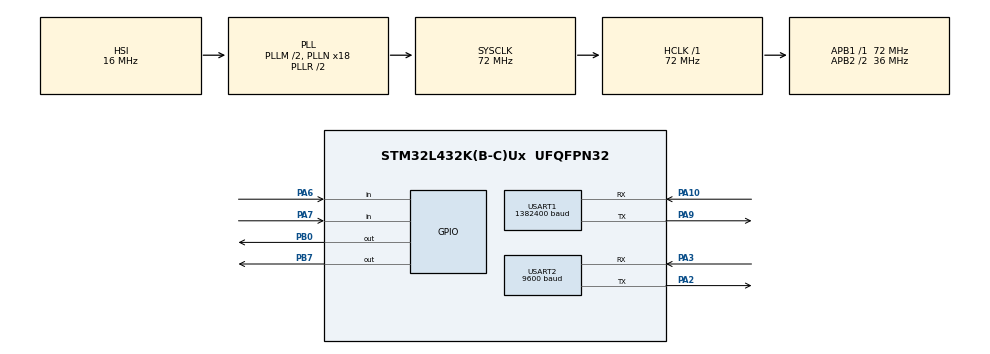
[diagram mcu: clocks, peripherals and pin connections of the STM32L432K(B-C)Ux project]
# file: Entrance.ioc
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Mcu.Family=STM32L4
Mcu.Name=STM32L432K(B-C)Ux
Mcu.Package=UFQFPN32
NVIC.PriorityGroup=NVIC_PRIORITYGROUP_4
NVIC.TIM1_CC_IRQn=true\:0\:0\:false\:false\:true\:true\:true
NVIC.USART1_IRQn=true\:0\:0\:false\:false\:true\:true\:true
NVIC.USART2_IRQn=true\:0\:0\:false\:false\:true\:true\:true
PA10.Mode=Asynchronous
PA10.Signal=USART1_RX
PA13\ (JTMS-SWDIO).Mode=Serial_Wire
PA13\ (JTMS-SWDIO).Signal=SYS_JTMS-SWDIO
PA14\ (JTCK-SWCLK).Mode=Serial_Wire
PA14\ (JTCK-SWCLK).Signal=SYS_JTCK-SWCLK
PA2.Mode=Asynchronous
PA2.Signal=USART2_TX
PA3.Mode=Asynchronous
PA3.Signal=USART2_RX
PA6.Signal=GPIO_Input
PA7.Signal=GPIO_Input
PA9.Mode=Asynchronous
PA9.Signal=USART1_TX
PB0.Signal=GPIO_Output
PB7.Signal=GPIO_Output
PC14-OSC32_IN\ (PC14).Mode=LSE-External-Oscillator
PC14-OSC32_IN\ (PC14).Signal=RCC_OSC32_IN
PC15-OSC32_OUT\ (PC15).Mode=LSE-External-Oscillator
PC15-OSC32_OUT\ (PC15).Signal=RCC_OSC32_OUT
ProjectManager.HeapSize=0x200
ProjectManager.StackSize=0x400
ProjectManager.TargetToolchain=MDK-ARM V5.27
RCC.ADCFreq_Value=32000000
RCC.AHBFreq_Value=72000000
RCC.APB1Freq_Value=72000000
RCC.APB1TimFreq_Value=72000000
RCC.APB2CLKDivider=RCC_HCLK_DIV2
RCC.APB2Freq_Value=36000000
RCC.APB2TimFreq_Value=72000000
RCC.CortexFreq_Value=72000000
RCC.HCLKFreq_Value=72000000
RCC.HSE_VALUE=8000000
RCC.HSI48_VALUE=48000000
RCC.HSI_VALUE=16000000
RCC.MSI_VALUE=4000000
RCC.PLLM=2
RCC.PLLN=18
RCC.PLLSourceVirtual=RCC_PLLSOURCE_HSI
RCC.SYSCLKFreq_VALUE=72000000
RCC.SYSCLKSource=RCC_SYSCLKSOURCE_PLLCLK
RCC.USBFreq_Value=32000000
RCC.VCOOutputFreq_Value=144000000
TIM1.Period=0xffff-1
TIM1.Prescaler=8-1
USART1.BaudRate=1382400
USART1.VirtualMode-Asynchronous=VM_ASYNC
USART2.BaudRate=9600
USART2.VirtualMode-Asynchronous=VM_ASYNC
VP_TIM1_VS_ClockSourceINT.Mode=Internal
board=custom

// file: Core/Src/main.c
/* USER CODE BEGIN Header */
/**
  ******************************************************************************
  * @file           : main.c
  * @brief          : Main program body
  ******************************************************************************
  * @attention
  *
  * <h2><center>&copy; Copyright (c) 2021 STMicroelectronics.
  * All rights reserved.</center></h2>
  *
  * This software component is licensed by ST under BSD 3-Clause license,
  * the "License"; You may not use this file except in compliance with the
  * License. You may obtain a copy of the License at:
  *                        opensource.org/licenses/BSD-3-Clause
  *
  ******************************************************************************
  */
/* USER CODE END Header */
#include "main.h"

/* USER CODE BEGIN PD */
#define IR1_PORT GPIOA
#define IR2_PORT GPIOA
#define IR1_PIN GPIO_PIN_7
#define IR2_PIN GPIO_PIN_6

#define LED1_PORT GPIOB
#define LED2_PORT GPIOB
#define LED1_PIN GPIO_PIN_0
#define LED2_PIN GPIO_PIN_7

/* USER CODE END PD */

TIM_HandleTypeDef htim1;

UART_HandleTypeDef huart1;
UART_HandleTypeDef huart2;

void SystemClock_Config(void);
static void MX_GPIO_Init(void);
static void MX_TIM1_Init(void);
static void MX_USART1_UART_Init(void);
static void MX_USART2_UART_Init(void);

int main(void)
{

  /* MCU Configuration--------------------------------------------------------*/

  /* Reset of all peripherals, Initializes the Flash interface and the Systick. */
  HAL_Init();

  /* Configure the system clock */
  SystemClock_Config();

  /* Initialize all configured peripherals */
  MX_GPIO_Init();
  MX_TIM1_Init();
  MX_USART1_UART_Init();
  MX_USART2_UART_Init();

  /* Infinite loop */
  while (1)
  {
    /* USER CODE BEGIN 3 */
			if(HAL_GPIO_ReadPin(IR1_PORT,IR1_PIN) == 1){
				HAL_GPIO_WritePin(LED1_PORT, LED1_PIN, 0);
			}
			else {
//				HAL_GPIO_WritePin(LED1_PORT, LED1_PIN, 1);
//			if(HAL_GPIO_ReadPin(IR2_PORT,IR2_PIN) == 1){
				HAL_GPIO_WritePin(LED2_PORT, LED2_PIN,0);
				HAL_UART_Transmit(&huart1,(uint8_t*)"exit",sizeof("exit"),HAL_MAX_DELAY);
//			}else {
//				HAL_GPIO_WritePin(LED2_PORT, LED2_PIN, 1);
//				HAL_UART_Transmit(&huart1,(uint8_t*)"exit",sizeof("exit"),HAL_MAX_DELAY);
//			}
			}

  }
  /* USER CODE END 3 */
}

void SystemClock_Config(void)
{
  RCC_OscInitTypeDef RCC_OscInitStruct = {0};
  RCC_ClkInitTypeDef RCC_ClkInitStruct = {0};
  RCC_PeriphCLKInitTypeDef PeriphClkInit = {0};

  /** Initializes the RCC Oscillators according to the specified parameters
  * in the RCC_OscInitTypeDef structure.
  */
  RCC_OscInitStruct.OscillatorType = RCC_OSCILLATORTYPE_HSI;
  RCC_OscInitStruct.HSIState = RCC_HSI_ON;
  RCC_OscInitStruct.HSICalibrationValue = RCC_HSICALIBRATION_DEFAULT;
  RCC_OscInitStruct.PLL.PLLState = RCC_PLL_ON;
  RCC_OscInitStruct.PLL.PLLSource = RCC_PLLSOURCE_HSI;
  RCC_OscInitStruct.PLL.PLLM = 2;
  RCC_OscInitStruct.PLL.PLLN = 18;
  RCC_OscInitStruct.PLL.PLLP = RCC_PLLP_DIV7;
  RCC_OscInitStruct.PLL.PLLQ = RCC_PLLQ_DIV2;
  RCC_OscInitStruct.PLL.PLLR = RCC_PLLR_DIV2;
  if (HAL_RCC_OscConfig(&RCC_OscInitStruct) != HAL_OK)
  {
    Error_Handler();
  }
  /** Initializes the CPU, AHB and APB buses clocks
  */
  RCC_ClkInitStruct.ClockType = RCC_CLOCKTYPE_HCLK|RCC_CLOCKTYPE_SYSCLK
                              |RCC_CLOCKTYPE_PCLK1|RCC_CLOCKTYPE_PCLK2;
  RCC_ClkInitStruct.SYSCLKSource = RCC_SYSCLKSOURCE_PLLCLK;
  RCC_ClkInitStruct.AHBCLKDivider = RCC_SYSCLK_DIV1;
  RCC_ClkInitStruct.APB1CLKDivider = RCC_HCLK_DIV1;
  RCC_ClkInitStruct.APB2CLKDivider = RCC_HCLK_DIV2;

  if (HAL_RCC_ClockConfig(&RCC_ClkInitStruct, FLASH_LATENCY_4) != HAL_OK)
  {
    Error_Handler();
  }
  PeriphClkInit.PeriphClockSelection = RCC_PERIPHCLK_USART1|RCC_PERIPHCLK_USART2;
  PeriphClkInit.Usart1ClockSelection = RCC_USART1CLKSOURCE_PCLK2;
  PeriphClkInit.Usart2ClockSelection = RCC_USART2CLKSOURCE_PCLK1;
  if (HAL_RCCEx_PeriphCLKConfig(&PeriphClkInit) != HAL_OK)
  {
    Error_Handler();
  }
  /** Configure the main internal regulator output voltage
  */
  if (HAL_PWREx_ControlVoltageScaling(PWR_REGULATOR_VOLTAGE_SCALE1) != HAL_OK)
  {
    Error_Handler();
  }
}

static void MX_TIM1_Init(void)
{

  TIM_ClockConfigTypeDef sClockSourceConfig = {0};
  TIM_MasterConfigTypeDef sMasterConfig = {0};

  htim1.Instance = TIM1;
  htim1.Init.Prescaler = 8-1;
  htim1.Init.CounterMode = TIM_COUNTERMODE_UP;
  htim1.Init.Period = 0xffff-1;
  htim1.Init.ClockDivision = TIM_CLOCKDIVISION_DIV1;
  htim1.Init.RepetitionCounter = 0;
  htim1.Init.AutoReloadPreload = TIM_AUTORELOAD_PRELOAD_DISABLE;
  if (HAL_TIM_Base_Init(&htim1) != HAL_OK)
  {
    Error_Handler();
  }
  sClockSourceConfig.ClockSource = TIM_CLOCKSOURCE_INTERNAL;
  if (HAL_TIM_ConfigClockSource(&htim1, &sClockSourceConfig) != HAL_OK)
  {
    Error_Handler();
  }
  sMasterConfig.MasterOutputTrigger = TIM_TRGO_RESET;
  sMasterConfig.MasterOutputTrigger2 = TIM_TRGO2_RESET;
  sMasterConfig.MasterSlaveMode = TIM_MASTERSLAVEMODE_DISABLE;
  if (HAL_TIMEx_MasterConfigSynchronization(&htim1, &sMasterConfig) != HAL_OK)
  {
    Error_Handler();
  }

}

static void MX_USART1_UART_Init(void)
{

  huart1.Instance = USART1;
  huart1.Init.BaudRate = 1382400;
  huart1.Init.WordLength = UART_WORDLENGTH_8B;
  huart1.Init.StopBits = UART_STOPBITS_1;
  huart1.Init.Parity = UART_PARITY_NONE;
  huart1.Init.Mode = UART_MODE_TX_RX;
  huart1.Init.HwFlowCtl = UART_HWCONTROL_NONE;
  huart1.Init.OverSampling = UART_OVERSAMPLING_16;
  huart1.Init.OneBitSampling = UART_ONE_BIT_SAMPLE_DISABLE;
  huart1.AdvancedInit.AdvFeatureInit = UART_ADVFEATURE_NO_INIT;
  if (HAL_UART_Init(&huart1) != HAL_OK)
  {
    Error_Handler();
  }

}

static void MX_USART2_UART_Init(void)
{

  huart2.Instance = USART2;
  huart2.Init.BaudRate = 9600;
  huart2.Init.WordLength = UART_WORDLENGTH_8B;
  huart2.Init.StopBits = UART_STOPBITS_1;
  huart2.Init.Parity = UART_PARITY_NONE;
  huart2.Init.Mode = UART_MODE_TX_RX;
  huart2.Init.HwFlowCtl = UART_HWCONTROL_NONE;
  huart2.Init.OverSampling = UART_OVERSAMPLING_16;
  huart2.Init.OneBitSampling = UART_ONE_BIT_SAMPLE_DISABLE;
  huart2.AdvancedInit.AdvFeatureInit = UART_ADVFEATURE_NO_INIT;
  if (HAL_UART_Init(&huart2) != HAL_OK)
  {
    Error_Handler();
  }

}

static void MX_GPIO_Init(void)
{
  GPIO_InitTypeDef GPIO_InitStruct = {0};

  /* GPIO Ports Clock Enable */
  __HAL_RCC_GPIOC_CLK_ENABLE();
  __HAL_RCC_GPIOA_CLK_ENABLE();
  __HAL_RCC_GPIOB_CLK_ENABLE();

  /*Configure GPIO pin Output Level */
  HAL_GPIO_WritePin(GPIOB, GPIO_PIN_0|GPIO_PIN_7, GPIO_PIN_RESET);

  /*Configure GPIO pins : PA6 PA7 */
  GPIO_InitStruct.Pin = GPIO_PIN_6|GPIO_PIN_7;
  GPIO_InitStruct.Mode = GPIO_MODE_INPUT;
  GPIO_InitStruct.Pull = GPIO_NOPULL;
  HAL_GPIO_Init(GPIOA, &GPIO_InitStruct);

  /*Configure GPIO pins : PB0 PB7 */
  GPIO_InitStruct.Pin = GPIO_PIN_0|GPIO_PIN_7;
  GPIO_InitStruct.Mode = GPIO_MODE_OUTPUT_PP;
  GPIO_InitStruct.Pull = GPIO_NOPULL;
  GPIO_InitStruct.Speed = GPIO_SPEED_FREQ_LOW;
  HAL_GPIO_Init(GPIOB, &GPIO_InitStruct);

}

void Error_Handler(void)
{
  __disable_irq();
  while (1)
  {
  }
}

/************************ (C) COPYRIGHT STMicroelectronics *****END OF FILE****/
